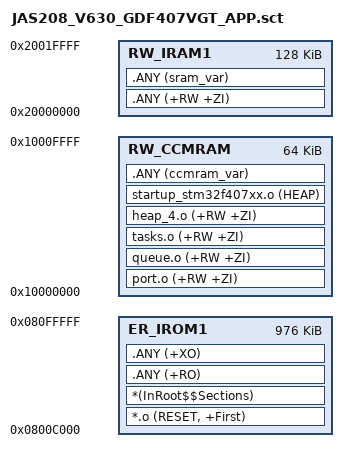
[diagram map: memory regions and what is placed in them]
; *************************************************************
; *** Scatter-Loading Description File generated by uVision ***
; *************************************************************

LR_IROM1 0x0800C000 0x000F4000  {    ; load region size_region
  ER_IROM1 0x0800C000 0x000F4000  {  ; load address = execution address
   *.o (RESET, +First)
   *(InRoot$$Sections)
   .ANY (+RO)
   .ANY (+XO)
  }
  RW_IRAM1 0x20000000 0x00020000  {  ; RW data
   .ANY (+RW +ZI)
   .ANY (sram_var)
  }
  RW_CCMRAM 0x10000000 0x00010000  {  ; RW data in CCM RAM
   port.o (+RW +ZI)
   queue.o (+RW +ZI)
   tasks.o (+RW +ZI)
   heap_4.o (+RW +ZI)
   startup_stm32f407xx.o (HEAP)
   .ANY (ccmram_var)
  }
}

